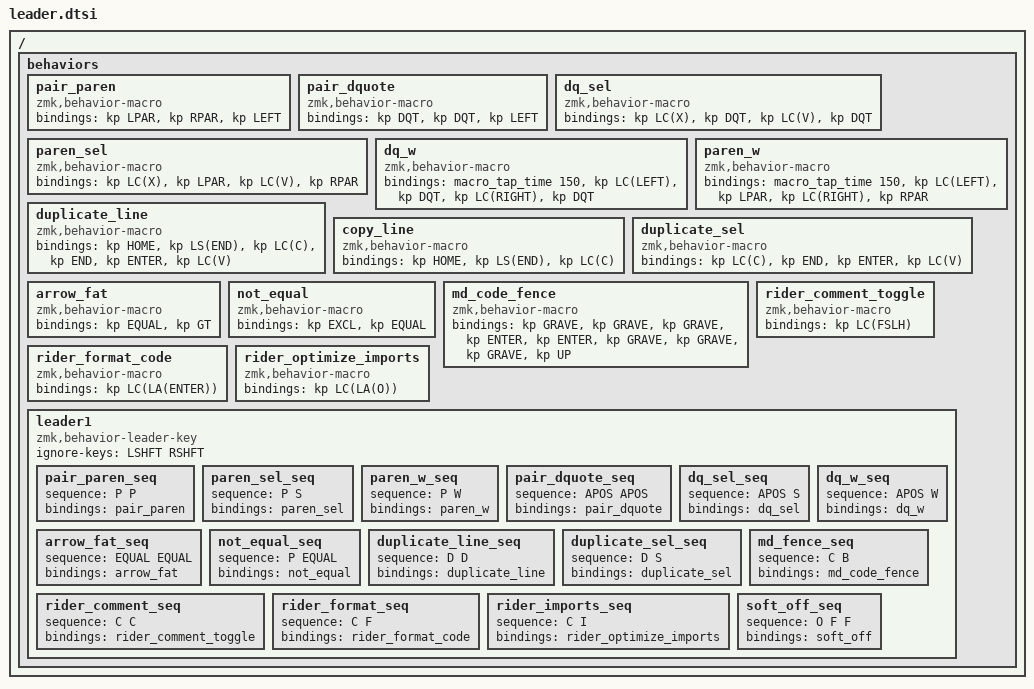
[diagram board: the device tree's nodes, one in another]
/* config/leader.dtsi
 * Windows-only. JetBrains Rider minimal.
 * Optional build.conf: CONFIG_ZMK_LEADER_TIMEOUT=1000
 */

 / {
  behaviors {
    /* ---------- Pair insertions ---------- */

    /* Pair () and place cursor inside */
    pair_paren: pair_paren {
      compatible = "zmk,behavior-macro";
      #binding-cells = <0>;
      bindings = <&kp LPAR &kp RPAR &kp LEFT>;
    };

    /* Pair "" and place cursor inside */
    pair_dquote: pair_dquote {
      compatible = "zmk,behavior-macro";
      #binding-cells = <0>;
      bindings = <&kp DQT &kp DQT &kp LEFT>;
    };

    /* ---------- Wrap SELECTION ---------- */

    /* Wrap selection with "" */
    dq_sel: dq_sel {
      compatible = "zmk,behavior-macro";
      #binding-cells = <0>;
      bindings = <&kp LC(X) &kp DQT &kp LC(V) &kp DQT>;
    };

    /* Wrap selection with () */
    paren_sel: paren_sel {
      compatible = "zmk,behavior-macro";
      #binding-cells = <0>;
      bindings = <&kp LC(X) &kp LPAR &kp LC(V) &kp RPAR>;
    };

    dq_w: dq_w {
      compatible = "zmk,behavior-macro";
      #binding-cells = <0>;
      bindings = <&macro_tap_time 150>,
        <
        &kp LC(LEFT)        /* Move to word start */
        &kp DQT             /* Type opening " */
        &kp LC(RIGHT)           /* Move cursor after word */
        &kp DQT             /* Type closing " */
        >;
    };
    
    paren_w: paren_w {
      compatible = "zmk,behavior-macro";
      #binding-cells = <0>;
      bindings = <&macro_tap_time 150>,
        <
        &kp LC(LEFT)        /* Move to word start */
        &kp LPAR             /* Type opening " */
        &kp LC(RIGHT)           /* Move cursor after word */
        &kp RPAR             /* Type closing " */
        >;
    };

    
    duplicate_line: duplicate_line {
        compatible = "zmk,behavior-macro";
        #binding-cells = <0>;
        bindings = <
            &kp HOME          // Move to start of line
            &kp LS(END)       // Select to end of line (Shift+End)
            &kp LC(C)         // Copy
            &kp END           // Move to end of line
            &kp ENTER         // New line
            &kp LC(V)         // Paste
        >;
    };

    copy_line: copy_line {
        compatible = "zmk,behavior-macro";
        #binding-cells = <0>;
        bindings = <
            &kp HOME          // Move to start of line
            &kp LS(END)       // Select to end of line (Shift+End)
            &kp LC(C)         // Copy
        >;
    };

    duplicate_sel: duplicate_sel {
        compatible = "zmk,behavior-macro";
        #binding-cells = <0>;
        bindings = <
            &kp LC(C)         // Copy
            &kp END           // Move to end of line
            &kp ENTER         // New line
            &kp LC(V)         // Paste
        >;
    };

    /* ---------- Other originals ---------- */

    /* => */
    arrow_fat: arrow_fat {
      compatible = "zmk,behavior-macro";
      #binding-cells = <0>;
      bindings = <&kp EQUAL &kp GT>;
    };

    not_equal: not_equal {
      compatible = "zmk,behavior-macro";
      #binding-cells = <0>;
      bindings = <&kp EXCL &kp EQUAL>;
    };


    /* ---------- Markdown (code-focused minimal) ---------- */

    /* Code fence block with cursor between fences */
    md_code_fence: md_code_fence {
      compatible = "zmk,behavior-macro";
      #binding-cells = <0>;
      bindings = <
        &kp GRAVE &kp GRAVE &kp GRAVE
        &kp ENTER &kp ENTER
        &kp GRAVE &kp GRAVE &kp GRAVE
        &kp UP
      >;
    };

    /* ---------- Rider (minimal) ---------- */

    /* Toggle line comment: Ctrl+/ */
    rider_comment_toggle: rider_comment_toggle {
      compatible = "zmk,behavior-macro";
      #binding-cells = <0>;
      bindings = <&kp LC(FSLH)>;
    };

    /* Format code: Ctrl+Alt+Enter */
    rider_format_code: rider_format_code {
      compatible = "zmk,behavior-macro";
      #binding-cells = <0>;
      bindings = <&kp LC(LA(ENTER))>;
    };

    /* Optimize imports: Ctrl+Alt+O */
    rider_optimize_imports: rider_optimize_imports {
      compatible = "zmk,behavior-macro";
      #binding-cells = <0>;
      bindings = <&kp LC(LA(O))>;
    };

    /* ---------- Leader + all sequences attached here ---------- */

    leader1: leader1 {
      compatible = "zmk,behavior-leader-key";
      #binding-cells = <0>;
      ignore-keys = <LSHFT RSHFT>;

      /* Text */
      pair_paren_seq   { sequence = <P P>;     bindings = <&pair_paren>;            };
      paren_sel_seq    { sequence = <P S>;     bindings = <&paren_sel>;             };
      paren_w_seq    { sequence = <P W>;     bindings = <&paren_w>;             };
      pair_dquote_seq  { sequence = <APOS APOS>;     bindings = <&pair_dquote>;           };
      dq_sel_seq       { sequence = <APOS S>;   bindings = <&dq_sel>;                };
      dq_w_seq       { sequence = <APOS W>;   bindings = <&dq_w>;                };
      arrow_fat_seq    { sequence = <EQUAL EQUAL>;     bindings = <&arrow_fat>;             };
      not_equal_seq    { sequence = <P EQUAL>;     bindings = <&not_equal>;             };
      duplicate_line_seq    { sequence = <D D>;     bindings = <&duplicate_line>;             };
      duplicate_sel_seq    { sequence = <D S>;     bindings = <&duplicate_sel>;             };

      /* Markdown (minimal) */
      md_fence_seq     { sequence = <C B>;     bindings = <&md_code_fence>;         };

      /* Rider (minimal) */
      rider_comment_seq{ sequence = <C C>;     bindings = <&rider_comment_toggle>;  };
      rider_format_seq { sequence = <C F>;     bindings = <&rider_format_code>;     };
      rider_imports_seq{ sequence = <C I>;     bindings = <&rider_optimize_imports>;};
      soft_off_seq{ sequence = <O F F>;     bindings = <&soft_off>;};
    };
  };
};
